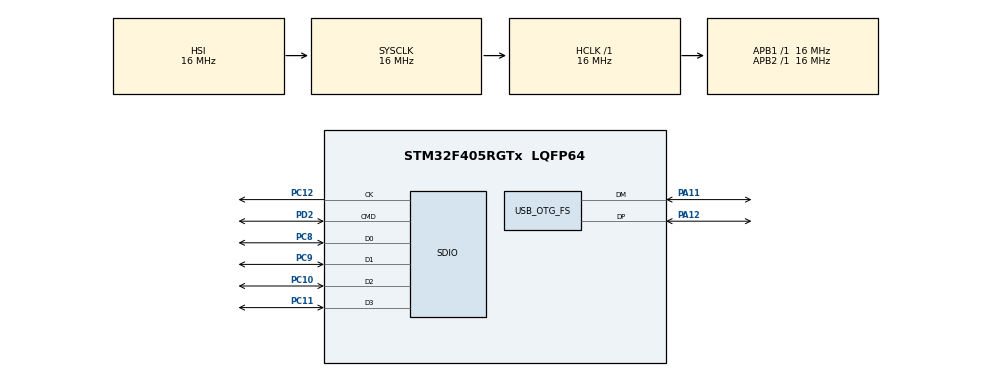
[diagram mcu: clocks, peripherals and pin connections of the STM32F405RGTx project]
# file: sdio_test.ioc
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Dma.Request0=SDIO_RX
Dma.Request1=SDIO_TX
Dma.SDIO_RX.0.Direction=DMA_PERIPH_TO_MEMORY
Dma.SDIO_RX.0.FIFOMode=DMA_FIFOMODE_ENABLE
Dma.SDIO_RX.0.FIFOThreshold=DMA_FIFO_THRESHOLD_FULL
Dma.SDIO_RX.0.Instance=DMA2_Stream3
Dma.SDIO_RX.0.MemBurst=DMA_MBURST_INC4
Dma.SDIO_RX.0.MemDataAlignment=DMA_MDATAALIGN_WORD
Dma.SDIO_RX.0.MemInc=DMA_MINC_ENABLE
Dma.SDIO_RX.0.Mode=DMA_PFCTRL
Dma.SDIO_RX.0.PeriphBurst=DMA_PBURST_INC4
Dma.SDIO_RX.0.PeriphDataAlignment=DMA_PDATAALIGN_WORD
Dma.SDIO_RX.0.PeriphInc=DMA_PINC_DISABLE
Dma.SDIO_RX.0.Priority=DMA_PRIORITY_LOW
Dma.SDIO_TX.1.Direction=DMA_MEMORY_TO_PERIPH
Dma.SDIO_TX.1.FIFOMode=DMA_FIFOMODE_ENABLE
Dma.SDIO_TX.1.FIFOThreshold=DMA_FIFO_THRESHOLD_FULL
Dma.SDIO_TX.1.Instance=DMA2_Stream6
Dma.SDIO_TX.1.MemBurst=DMA_MBURST_INC4
Dma.SDIO_TX.1.MemDataAlignment=DMA_MDATAALIGN_WORD
Dma.SDIO_TX.1.MemInc=DMA_MINC_ENABLE
Dma.SDIO_TX.1.Mode=DMA_PFCTRL
Dma.SDIO_TX.1.PeriphBurst=DMA_PBURST_INC4
Dma.SDIO_TX.1.PeriphDataAlignment=DMA_PDATAALIGN_WORD
Dma.SDIO_TX.1.PeriphInc=DMA_PINC_DISABLE
Dma.SDIO_TX.1.Priority=DMA_PRIORITY_LOW
FATFS.USE_DMA_CODE_SD=1
FATFS._MAX_SS=4096
FATFS._USE_LFN=1
Mcu.Family=STM32F4
Mcu.Name=STM32F405RGTx
Mcu.Package=LQFP64
NVIC.DMA2_Stream3_IRQn=true\:0\:0\:false\:false\:true\:false\:true\:true
NVIC.DMA2_Stream6_IRQn=true\:0\:0\:false\:false\:true\:false\:true\:true
NVIC.OTG_FS_IRQn=true\:0\:0\:false\:false\:true\:false\:true\:true
NVIC.PriorityGroup=NVIC_PRIORITYGROUP_4
NVIC.SDIO_IRQn=true\:0\:0\:false\:false\:true\:true\:true\:true
PA11.Mode=Device_Only
PA11.Signal=USB_OTG_FS_DM
PA12.Mode=Device_Only
PA12.Signal=USB_OTG_FS_DP
PC10.GPIO_PuPd=GPIO_PULLUP
PC10.Mode=SD_4_bits_Wide_bus
PC10.Signal=SDIO_D2
PC11.GPIO_PuPd=GPIO_PULLUP
PC11.Mode=SD_4_bits_Wide_bus
PC11.Signal=SDIO_D3
PC12.Mode=SD_4_bits_Wide_bus
PC12.Signal=SDIO_CK
PC14-OSC32_IN.Mode=LSE-External-Oscillator
PC14-OSC32_IN.Signal=RCC_OSC32_IN
PC15-OSC32_OUT.Mode=LSE-External-Oscillator
PC15-OSC32_OUT.Signal=RCC_OSC32_OUT
PC8.GPIO_PuPd=GPIO_PULLUP
PC8.Mode=SD_4_bits_Wide_bus
PC8.Signal=SDIO_D0
PC9.GPIO_PuPd=GPIO_PULLUP
PC9.Mode=SD_4_bits_Wide_bus
PC9.Signal=SDIO_D1
PD2.GPIO_PuPd=GPIO_PULLUP
PD2.Mode=SD_4_bits_Wide_bus
PD2.Signal=SDIO_CMD
PH0-OSC_IN.Mode=HSE-External-Oscillator
PH0-OSC_IN.Signal=RCC_OSC_IN
PH1-OSC_OUT.Mode=HSE-External-Oscillator
PH1-OSC_OUT.Signal=RCC_OSC_OUT
ProjectManager.HeapSize=0x200
ProjectManager.StackSize=0x400
ProjectManager.TargetToolchain=CMake
RCC.48MHZClocksFreq_Value=48000000
RCC.AHBFreq_Value=16000000
RCC.APB1Freq_Value=16000000
RCC.APB2Freq_Value=16000000
RCC.CortexFreq_Value=16000000
RCC.HSE_VALUE=12000000
RCC.HSI_VALUE=16000000
RCC.PLLM=6
RCC.PLLN=72
RCC.PLLQ=3
RCC.SYSCLKFreq_VALUE=16000000
RCC.VCOOutputFreq_Value=144000000
USB_DEVICE.CLASS_NAME_FS=CDC
USB_DEVICE.VirtualMode-CDC_FS=Cdc
USB_DEVICE.VirtualModeFS=Cdc_FS
USB_OTG_FS.VirtualMode=Device_Only
VP_FATFS_VS_SDIO.Mode=SDIO
VP_USB_DEVICE_VS_USB_DEVICE_CDC_FS.Mode=CDC_FS
board=custom

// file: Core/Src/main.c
/* USER CODE BEGIN Header */
/**
  ******************************************************************************
  * @file           : main.c
  * @brief          : Main program body
  ******************************************************************************
  * @attention
  *
  * Copyright (c) 2025 STMicroelectronics.
  * All rights reserved.
  *
  * This software is licensed under terms that can be found in the LICENSE file
  * in the root directory of this software component.
  * If no LICENSE file comes with this software, it is provided AS-IS.
  *
  ******************************************************************************
  */
/* USER CODE END Header */
#include "main.h"
#include "fatfs.h"
#include "usb_device.h"
#include "usbd_cdc_if.h"
#include <stdio.h>
#include <string.h>

SD_HandleTypeDef hsd;
DMA_HandleTypeDef hdma_sdio_rx;
DMA_HandleTypeDef hdma_sdio_tx;
char TxBuffer[250];

void SystemClock_Config(void);
static void MX_GPIO_Init(void);
static void MX_DMA_Init(void);
static void MX_SDIO_SD_Init(void);
static void SDIO_SDCard_Test(void);

static void USB_CDC_Print(char* TxStr)
{
  while(CDC_Transmit_FS((uint8_t*)TxStr, strlen(TxStr)) == USBD_BUSY);
}

int main(void)
{

  /* MCU Configuration--------------------------------------------------------*/

  /* Reset of all peripherals, Initializes the Flash interface and the Systick. */
  HAL_Init();

  /* Configure the system clock */
  SystemClock_Config();

  /* Initialize all configured peripherals */
  MX_GPIO_Init();
  MX_DMA_Init();
  MX_SDIO_SD_Init();
  MX_FATFS_Init();
  MX_USB_DEVICE_Init();
  /* USER CODE BEGIN 2 */
  // Test The SDIO SD Card Interface
  HAL_Delay(5000); // This delay is not mandatory but it gives me some time to connect the USB cable and open the terminal
  SDIO_SDCard_Test();
  /* USER CODE END 2 */

  /* Infinite loop */
  while (1)
  {

  }
}

static void SDIO_SDCard_Test(void)
{
  FATFS FatFs;
  FIL Fil;
  FRESULT FR_Status;
  FATFS *FS_Ptr;
  UINT RWC, WWC; // Read/Write Word Counter
  DWORD FreeClusters;
  uint32_t TotalSize, FreeSpace;
  char RW_Buffer[200];
  do
  {
    //------------------[ Mount The SD Card ]--------------------
    FR_Status = f_mount(&FatFs, SDPath, 1);
    if (FR_Status != FR_OK)
    {
      sprintf(TxBuffer, "Error! While Mounting SD Card, Error Code: (%i)\r\n", FR_Status);
      USB_CDC_Print(TxBuffer);
      break;
    }
    sprintf(TxBuffer, "SD Card Mounted Successfully! \r\n\n");
    USB_CDC_Print(TxBuffer);
    //------------------[ Get & Print The SD Card Size & Free Space ]--------------------
    f_getfree("", &FreeClusters, &FS_Ptr);
    TotalSize = (uint32_t)((FS_Ptr->n_fatent - 2) * FS_Ptr->csize * 0.5);
    FreeSpace = (uint32_t)(FreeClusters * FS_Ptr->csize * 0.5);
    sprintf(TxBuffer, "Total SD Card Size: %lu Bytes\r\n", TotalSize);
    USB_CDC_Print(TxBuffer);
    sprintf(TxBuffer, "Free SD Card Space: %lu Bytes\r\n\n", FreeSpace);
    USB_CDC_Print(TxBuffer);
    //------------------[ Open A Text File For Write & Write Data ]--------------------
    //Open the file
    FR_Status = f_open(&Fil, "MyTextFile.txt", FA_WRITE | FA_READ | FA_CREATE_ALWAYS);
    if(FR_Status != FR_OK)
    {
      sprintf(TxBuffer, "Error! While Creating/Opening A New Text File, Error Code: (%i)\r\n", FR_Status);
      USB_CDC_Print(TxBuffer);
      break;
    }
    sprintf(TxBuffer, "Text File Created & Opened! Writing Data To The Text File..\r\n\n");
    USB_CDC_Print(TxBuffer);
    // (1) Write Data To The Text File [ Using f_puts() Function ]
    f_puts("Hello! From STM32 To SD Card Over SDIO + DMA, Using f_puts()\n", &Fil);
    // (2) Write Data To The Text File [ Using f_write() Function ]
    strcpy(RW_Buffer, "Hello! From STM32 To SD Card Over SDIO + DMA, Using f_write()\r\n");
    f_write(&Fil, RW_Buffer, strlen(RW_Buffer), &WWC);
    // Close The File
    f_close(&Fil);
    //------------------[ Open A Text File For Read & Read Its Data ]--------------------
    // Open The File
    FR_Status = f_open(&Fil, "MyTextFile.txt", FA_READ);
    if(FR_Status != FR_OK)
    {
      sprintf(TxBuffer, "Error! While Opening (MyTextFile.txt) File For Read.. \r\n");
      USB_CDC_Print(TxBuffer);
      break;
    }
    // (1) Read The Text File's Data [ Using f_gets() Function ]
    f_gets(RW_Buffer, sizeof(RW_Buffer), &Fil);
    sprintf(TxBuffer, "Data Read From (MyTextFile.txt) Using f_gets():%s", RW_Buffer);
    USB_CDC_Print(TxBuffer);
    // (2) Read The Text File's Data [ Using f_read() Function ]
    f_read(&Fil, RW_Buffer, f_size(&Fil), &RWC);
    sprintf(TxBuffer, "Data Read From (MyTextFile.txt) Using f_read():%s", RW_Buffer);
    USB_CDC_Print(TxBuffer);
    // Close The File
    f_close(&Fil);
    sprintf(TxBuffer, "File Closed! \r\n\n");
    USB_CDC_Print(TxBuffer);
    //------------------[ Open An Existing Text File, Update Its Content, Read It Back ]--------------------
    // (1) Open The Existing File For Write (Update)
    FR_Status = f_open(&Fil, "MyTextFile.txt", FA_OPEN_EXISTING | FA_WRITE);
    FR_Status = f_lseek(&Fil, f_size(&Fil)); // Move The File Pointer To The EOF (End-Of-File)
    if(FR_Status != FR_OK)
    {
      sprintf(TxBuffer, "Error! While Opening (MyTextFile.txt) File For Update.. \r\n");
      USB_CDC_Print(TxBuffer);
      break;
    }
    // (2) Write New Line of Text Data To The File
    FR_Status = f_puts("This New Line Was Added During File Update!\r\n", &Fil);
    f_close(&Fil);
    memset(RW_Buffer,'\0',sizeof(RW_Buffer)); // Clear The Buffer
    // (3) Read The Contents of The Text File After The Update
    FR_Status = f_open(&Fil, "MyTextFile.txt", FA_READ); // Open The File For Read
    f_read(&Fil, RW_Buffer, f_size(&Fil), &RWC);
    sprintf(TxBuffer, "Data Read From (MyTextFile.txt) After Update:\r\n%s", RW_Buffer);
    USB_CDC_Print(TxBuffer);
    f_close(&Fil);
    //------------------[ Delete The Text File ]--------------------
    // Delete The File
    /*
    FR_Status = f_unlink(MyTextFile.txt);
    if (FR_Status != FR_OK){
        sprintf(TxBuffer, "Error! While Deleting The (MyTextFile.txt) File.. \r\n");
        USC_CDC_Print(TxBuffer);
    }
    */
  } while(0);
  //------------------[ Test Complete! Unmount The SD Card ]--------------------
  FR_Status = f_mount(NULL, "", 0);
  if (FR_Status != FR_OK)
  {
      sprintf(TxBuffer, "\r\nError! While Un-mounting SD Card, Error Code: (%i)\r\n", FR_Status);
      USB_CDC_Print(TxBuffer);
  } else{
      sprintf(TxBuffer, "\r\nSD Card Un-mounted Successfully! \r\n");
      USB_CDC_Print(TxBuffer);
  }
}

void SystemClock_Config(void)
{
  RCC_OscInitTypeDef RCC_OscInitStruct = {0};
  RCC_ClkInitTypeDef RCC_ClkInitStruct = {0};

  /** Configure the main internal regulator output voltage
  */
  __HAL_RCC_PWR_CLK_ENABLE();
  __HAL_PWR_VOLTAGESCALING_CONFIG(PWR_REGULATOR_VOLTAGE_SCALE1);

  /** Initializes the RCC Oscillators according to the specified parameters
  * in the RCC_OscInitTypeDef structure.
  */
  RCC_OscInitStruct.OscillatorType = RCC_OSCILLATORTYPE_HSI|RCC_OSCILLATORTYPE_HSE;
  RCC_OscInitStruct.HSEState = RCC_HSE_ON;
  RCC_OscInitStruct.HSIState = RCC_HSI_ON;
  RCC_OscInitStruct.HSICalibrationValue = RCC_HSICALIBRATION_DEFAULT;
  RCC_OscInitStruct.PLL.PLLState = RCC_PLL_ON;
  RCC_OscInitStruct.PLL.PLLSource = RCC_PLLSOURCE_HSE;
  RCC_OscInitStruct.PLL.PLLM = 6;
  RCC_OscInitStruct.PLL.PLLN = 72;
  RCC_OscInitStruct.PLL.PLLP = RCC_PLLP_DIV2;
  RCC_OscInitStruct.PLL.PLLQ = 3;
  if (HAL_RCC_OscConfig(&RCC_OscInitStruct) != HAL_OK)
  {
    Error_Handler();
  }

  /** Initializes the CPU, AHB and APB buses clocks
  */
  RCC_ClkInitStruct.ClockType = RCC_CLOCKTYPE_HCLK|RCC_CLOCKTYPE_SYSCLK
                              |RCC_CLOCKTYPE_PCLK1|RCC_CLOCKTYPE_PCLK2;
  RCC_ClkInitStruct.SYSCLKSource = RCC_SYSCLKSOURCE_HSI;
  RCC_ClkInitStruct.AHBCLKDivider = RCC_SYSCLK_DIV1;
  RCC_ClkInitStruct.APB1CLKDivider = RCC_HCLK_DIV1;
  RCC_ClkInitStruct.APB2CLKDivider = RCC_HCLK_DIV1;

  if (HAL_RCC_ClockConfig(&RCC_ClkInitStruct, FLASH_LATENCY_0) != HAL_OK)
  {
    Error_Handler();
  }
}

static void MX_SDIO_SD_Init(void)
{

  hsd.Instance = SDIO;
  hsd.Init.ClockEdge = SDIO_CLOCK_EDGE_RISING;
  hsd.Init.ClockBypass = SDIO_CLOCK_BYPASS_DISABLE;
  hsd.Init.ClockPowerSave = SDIO_CLOCK_POWER_SAVE_DISABLE;
  hsd.Init.BusWide = SDIO_BUS_WIDE_1B;
  hsd.Init.HardwareFlowControl = SDIO_HARDWARE_FLOW_CONTROL_DISABLE;
  hsd.Init.ClockDiv = 8;
  /* USER CODE BEGIN SDIO_Init 2 */
  if (HAL_SD_Init(&hsd) != HAL_OK) {
    Error_Handler();
  }

  // Switch to 4-bit after successful init
  if (HAL_SD_ConfigWideBusOperation(&hsd, SDIO_BUS_WIDE_4B) != HAL_OK) {
    Error_Handler();
  }
  /* USER CODE END SDIO_Init 2 */

}

static void MX_DMA_Init(void)
{

  /* DMA controller clock enable */
  __HAL_RCC_DMA2_CLK_ENABLE();

  /* DMA interrupt init */
  /* DMA2_Stream3_IRQn interrupt configuration */
  HAL_NVIC_SetPriority(DMA2_Stream3_IRQn, 0, 0);
  HAL_NVIC_EnableIRQ(DMA2_Stream3_IRQn);
  /* DMA2_Stream6_IRQn interrupt configuration */
  HAL_NVIC_SetPriority(DMA2_Stream6_IRQn, 0, 0);
  HAL_NVIC_EnableIRQ(DMA2_Stream6_IRQn);

}

static void MX_GPIO_Init(void)
{

  /* GPIO Ports Clock Enable */
  __HAL_RCC_GPIOC_CLK_ENABLE();
  __HAL_RCC_GPIOH_CLK_ENABLE();
  __HAL_RCC_GPIOA_CLK_ENABLE();
  __HAL_RCC_GPIOD_CLK_ENABLE();

}

void Error_Handler(void)
{
  __disable_irq();
  while (1)
  {
  }
}
